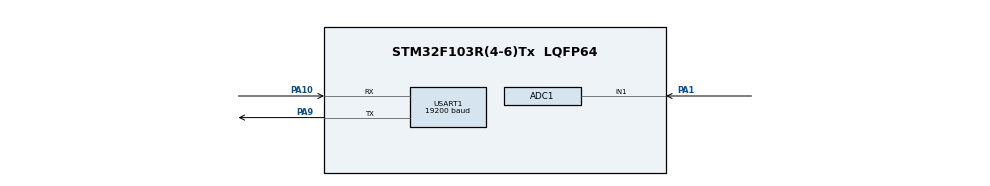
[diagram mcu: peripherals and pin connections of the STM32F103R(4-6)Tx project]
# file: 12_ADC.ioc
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ADC1.Channel-0\#ChannelRegularConversion=ADC_CHANNEL_1
ADC1.NbrOfConversionFlag=1
ADC1.Rank-0\#ChannelRegularConversion=1
ADC1.SamplingTime-0\#ChannelRegularConversion=ADC_SAMPLETIME_1CYCLE_5
ADC1.master=1
Mcu.Family=STM32F1
Mcu.Name=STM32F103R(4-6)Tx
Mcu.Package=LQFP64
NVIC.PriorityGroup=NVIC_PRIORITYGROUP_4
NVIC.USART1_IRQn=true\:0\:0\:false\:false\:true\:true\:true\:true
PA1.Signal=ADCx_IN1
PA10.Mode=Asynchronous
PA10.Signal=USART1_RX
PA9.Mode=Asynchronous
PA9.Signal=USART1_TX
ProjectManager.HeapSize=0x200
ProjectManager.StackSize=0x400
ProjectManager.TargetToolchain=MDK-ARM V5.32
RCC.APB1Freq_Value=8000000
RCC.APB2Freq_Value=8000000
SH.ADCx_IN1.0=ADC1_IN1,IN1
USART1.BaudRate=19200
USART1.VirtualMode=VM_ASYNC
VP_SYS_VS_ND.Mode=No_Debug
board=custom

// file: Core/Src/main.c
/* USER CODE BEGIN Header */
/**
  ******************************************************************************
  * @file           : main.c
  * @brief          : Main program body
  ******************************************************************************
  * @attention
  *
  * Copyright (c) 2022 STMicroelectronics.
  * All rights reserved.
  *
  * This software is licensed under terms that can be found in the LICENSE file
  * in the root directory of this software component.
  * If no LICENSE file comes with this software, it is provided AS-IS.
  *
  ******************************************************************************
  */
/* USER CODE END Header */
#include "stdio.h"
#include "main.h"
#include "adc.h"
#include "usart.h"
#include "gpio.h"

/* USER CODE BEGIN PV */
//温度t-数字量D关系数组
const uint32_t tD[]=
{
	3178,  //t=0
	3139, 3099, 3059, 3017, 2975, 2932, 2888, 2844, 2799, 2754,  //t=1~10
	2708, 2662, 2615, 2569, 2521, 2474, 2427, 2379, 2331, 2284,  //t=11~20
	2236, 2189, 2141, 2094, 2048, 2001, 1955, 1909, 1864, 1819,  //t=21~30
	1775, 1731, 1688, 1645, 1603, 1562, 1522, 1482, 1442, 1404   //t=31~40
};
/* USER CODE END PV */

void SystemClock_Config(void);
/* USER CODE BEGIN PFP */
float D2t(uint32_t D);  //自定义函数，根据ADC转换结果计算温度值
/* USER CODE END PFP */

int main(void)
{
  /* USER CODE BEGIN 1 */
	ADC_ChannelConfTypeDef sConfig = {0};  //建立sConfig结构体
	char str[20];  //温度值转换为字符串的存放数组
	float t;  //计算得出的温度值
	uint32_t adcv;  //存放ADC转换结果
  /* USER CODE END 1 */

  /* MCU Configuration--------------------------------------------------------*/

  /* Reset of all peripherals, Initializes the Flash interface and the Systick. */
  HAL_Init();

  /* USER CODE BEGIN Init */
	sConfig.Rank = ADC_REGULAR_RANK_1;
	sConfig.SamplingTime = ADC_SAMPLETIME_1CYCLE_5;  //采样周期为1.5个周期
  /* USER CODE END Init */

  /* Configure the system clock */
  SystemClock_Config();

  /* Initialize all configured peripherals */
  MX_GPIO_Init();
  MX_ADC1_Init();
  MX_USART1_UART_Init();

  /* Infinite loop */
  /* USER CODE BEGIN WHILE */
  while (1)
  {
		sConfig.Channel = ADC_CHANNEL_1;  //选择通道1
		HAL_ADC_ConfigChannel(&hadc1, &sConfig);  //选择ADC1的通道1
		HAL_ADC_Start(&hadc1);										//启动ADC1
		HAL_ADC_PollForConversion(&hadc1, 10);		//等待ADC1转换结束，超时设定为10ms
		adcv = HAL_ADC_GetValue(&hadc1);					//读取ADC1的转换结果
		HAL_ADC_Stop(&hadc1);											//停止ADC1
		t = D2t(adcv);														//计算温度值
		sprintf(str,"%f",t);											//将浮点型变量t转换为字符串并写入字符串数组str中
		HAL_UART_Transmit(&huart1, (uint8_t *)&"temperature:", 12, 10);  //串口1发送字符串，数组长度为12，超时10ms
		HAL_UART_Transmit(&huart1, (uint8_t *)str, 5, 10);								//串口1发送字符串，数组长度为5，超时10ms
		HAL_UART_Transmit(&huart1, (uint8_t *)&"\n\r", 2, 10);						//串口1发送字符串，数组长度为2，超时10ms
		HAL_Delay(1000);
    /* USER CODE END WHILE */

  }
}

void SystemClock_Config(void)
{
  RCC_OscInitTypeDef RCC_OscInitStruct = {0};
  RCC_ClkInitTypeDef RCC_ClkInitStruct = {0};
  RCC_PeriphCLKInitTypeDef PeriphClkInit = {0};

  /** Initializes the RCC Oscillators according to the specified parameters
  * in the RCC_OscInitTypeDef structure.
  */
  RCC_OscInitStruct.OscillatorType = RCC_OSCILLATORTYPE_HSI;
  RCC_OscInitStruct.HSIState = RCC_HSI_ON;
  RCC_OscInitStruct.HSICalibrationValue = RCC_HSICALIBRATION_DEFAULT;
  RCC_OscInitStruct.PLL.PLLState = RCC_PLL_NONE;
  if (HAL_RCC_OscConfig(&RCC_OscInitStruct) != HAL_OK)
  {
    Error_Handler();
  }

  /** Initializes the CPU, AHB and APB buses clocks
  */
  RCC_ClkInitStruct.ClockType = RCC_CLOCKTYPE_HCLK|RCC_CLOCKTYPE_SYSCLK
                              |RCC_CLOCKTYPE_PCLK1|RCC_CLOCKTYPE_PCLK2;
  RCC_ClkInitStruct.SYSCLKSource = RCC_SYSCLKSOURCE_HSI;
  RCC_ClkInitStruct.AHBCLKDivider = RCC_SYSCLK_DIV1;
  RCC_ClkInitStruct.APB1CLKDivider = RCC_HCLK_DIV1;
  RCC_ClkInitStruct.APB2CLKDivider = RCC_HCLK_DIV1;

  if (HAL_RCC_ClockConfig(&RCC_ClkInitStruct, FLASH_LATENCY_0) != HAL_OK)
  {
    Error_Handler();
  }
  PeriphClkInit.PeriphClockSelection = RCC_PERIPHCLK_ADC;
  PeriphClkInit.AdcClockSelection = RCC_ADCPCLK2_DIV2;
  if (HAL_RCCEx_PeriphCLKConfig(&PeriphClkInit) != HAL_OK)
  {
    Error_Handler();
  }
}

/* USER CODE BEGIN 4 */
//根据ADC转换结果计算温度值
float D2t(uint32_t D)
{
	uint32_t D1,D2,i;
	float t=0, t1;
	for(i=0;i<=39;i++)
	{
		if(D>=tD[i+1] && D<=tD[i])
		{
			D1 = tD[i];
			D2 = tD[i+1];
			t1 = (float)i;
			t = (float)(D1-D)/(float)(D1-D2)+t1;
			break;
		}
	}
	return t;
}
/* USER CODE END 4 */

void Error_Handler(void)
{
  __disable_irq();
  while (1)
  {
  }
}
